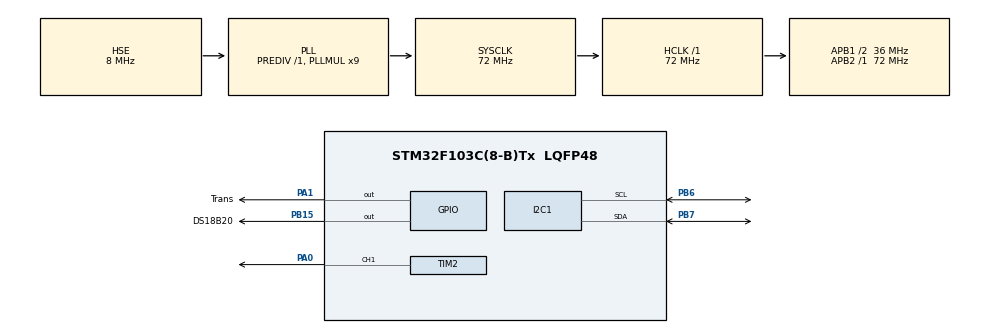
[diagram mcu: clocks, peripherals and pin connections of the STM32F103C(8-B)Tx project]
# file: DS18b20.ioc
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Mcu.Family=STM32F1
Mcu.Name=STM32F103C(8-B)Tx
Mcu.Package=LQFP48
NVIC.PriorityGroup=NVIC_PRIORITYGROUP_4
PA0-WKUP.Signal=S_TIM2_CH1_ETR
PA1.GPIO_Label=Trans
PA1.PinState=GPIO_PIN_RESET
PA1.Signal=GPIO_Output
PA13.Mode=Serial_Wire
PA13.Signal=SYS_JTMS-SWDIO
PA14.Mode=Serial_Wire
PA14.Signal=SYS_JTCK-SWCLK
PB15.GPIO_Label=DS18B20
PB15.Signal=GPIO_Output
PB6.Mode=I2C
PB6.Signal=I2C1_SCL
PB7.Mode=I2C
PB7.Signal=I2C1_SDA
PD0-OSC_IN.Mode=HSE-External-Oscillator
PD0-OSC_IN.Signal=RCC_OSC_IN
PD1-OSC_OUT.Mode=HSE-External-Oscillator
PD1-OSC_OUT.Signal=RCC_OSC_OUT
ProjectManager.HeapSize=0x200
ProjectManager.StackSize=0x400
ProjectManager.TargetToolchain=MDK-ARM V5
RCC.AHBFreq_Value=72000000
RCC.APB1CLKDivider=RCC_HCLK_DIV2
RCC.APB1Freq_Value=36000000
RCC.APB1TimFreq_Value=72000000
RCC.APB2Freq_Value=72000000
RCC.APB2TimFreq_Value=72000000
RCC.HCLKFreq_Value=72000000
RCC.PLLMUL=RCC_PLL_MUL9
RCC.PLLSourceVirtual=RCC_PLLSOURCE_HSE
RCC.SYSCLKFreq_VALUE=72000000
RCC.SYSCLKSource=RCC_SYSCLKSOURCE_PLLCLK
RCC.USBFreq_Value=72000000
SH.S_TIM2_CH1_ETR.0=TIM2_CH1,PWM Generation1 CH1
TIM2.Channel-PWM\ Generation1\ CH1=TIM_CHANNEL_1
TIM2.Period=99
TIM2.Prescaler=8000
TIM2.Pulse-PWM\ Generation1\ CH1=25
TIM4.Prescaler=72-1
VP_TIM2_VS_ClockSourceINT.Mode=Internal
VP_TIM4_VS_ClockSourceINT.Mode=Internal
board=custom

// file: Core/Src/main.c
/* USER CODE BEGIN Header */
/**
  ******************************************************************************
  * @file           : main.c
  * @brief          : Main program body
  ******************************************************************************
  * @attention
  *
  * <h2><center>&copy; Copyright (c) 2023 STMicroelectronics.
  * All rights reserved.</center></h2>
  *
  * This software component is licensed by ST under BSD 3-Clause license,
  * the "License"; You may not use this file except in compliance with the
  * License. You may obtain a copy of the License at:
  *                        opensource.org/licenses/BSD-3-Clause
  *
  ******************************************************************************
  */
/* USER CODE END Header */
#include "main.h"
#include "i2c-lcd.h"
#include "DS18B20.h"
#include "delay_timer.h"
#include "stdio.h"

I2C_HandleTypeDef hi2c1;
TIM_HandleTypeDef htim2;
TIM_HandleTypeDef htim4;

/* USER CODE BEGIN PV */
DS18B20_Name DS1;
float Temp;
float setpoint_temperature = 25;  // Giá tr? m?c tiêu nhi?t d?
float Kp = 1.2;                      // H? s? Proportional
float Ki = 0.1;                      // H? s? Integral
float Kd = 25;                     // H? s? Derivative

float prev_error = 0.0;
float integral = 0.0;
/* USER CODE END PV */

void SystemClock_Config(void);
static void MX_GPIO_Init(void);
static void MX_TIM4_Init(void);
static void MX_I2C1_Init(void);
static void MX_TIM2_Init(void);
void PID_Control(float current_temperature) {
    float error = - setpoint_temperature + current_temperature;
    float pid_output = Kp * error + Ki * integral + Kd * (error - prev_error);

    // Gi? l?i giá tr? PID trong m?c cho phép
    if (pid_output > 100.0) {
        pid_output = 100.0;
    } else if (pid_output < 0.0) {
        pid_output = 0.0;
    }

    // C?p nh?t giá tr? integral và l?i tru?c dó
    integral += error;
    prev_error = error;

    // Áp d?ng giá tr? PID d? di?u khi?n xung PWM
    __HAL_TIM_SET_COMPARE(&htim2, TIM_CHANNEL_1, (uint32_t)(pid_output * htim2.Init.Period / 100.0));
}

int main(void)
{

  /* MCU Configuration--------------------------------------------------------*/

  /* Reset of all peripherals, Initializes the Flash interface and the Systick. */
  HAL_Init();

  /* Configure the system clock */
  SystemClock_Config();

  /* Initialize all configured peripherals */
  MX_GPIO_Init();
  MX_TIM4_Init();
  MX_I2C1_Init();
  MX_TIM2_Init();
	lcd_init();
	HAL_TIM_PWM_Start(&htim2, TIM_CHANNEL_1);
  /* USER CODE BEGIN 2 */
DS18B20_Init(&DS1, &htim4, DS18B20_GPIO_Port, DS18B20_Pin);
char dulieu[20];
  /* USER CODE END 2 */

  /* Infinite loop */
  while (1)
  {
				Temp = DS18B20_ReadTemp(&DS1);
				lcd_clear();
			  lcd_put_cur(0,4);
		    lcd_send_string("DS18B21");
		    lcd_put_cur(1,2);
        lcd_send_string("T = ");
        lcd_put_cur(1,11);
        lcd_send_data(223);
        lcd_put_cur(1,12);
        lcd_send_string("C");
				PID_Control(Temp);
				sprintf(dulieu,"%2.2f",Temp);
		    lcd_send_cmd(0x80|0x46);
		    lcd_send_string(dulieu);
				if (Temp <=30 ) HAL_GPIO_WritePin(Trans_GPIO_Port,Trans_Pin,1);
				else if (Temp >=35 ) HAL_GPIO_WritePin(Trans_GPIO_Port,Trans_Pin,0);
				HAL_Delay(1000);
    /* USER CODE BEGIN 3 */
    /* USER CODE BEGIN 3 */
  }
  /* USER CODE END 3 */
}

void SystemClock_Config(void)
{
  RCC_OscInitTypeDef RCC_OscInitStruct = {0};
  RCC_ClkInitTypeDef RCC_ClkInitStruct = {0};

  /** Initializes the RCC Oscillators according to the specified parameters
  * in the RCC_OscInitTypeDef structure.
  */
  RCC_OscInitStruct.OscillatorType = RCC_OSCILLATORTYPE_HSE;
  RCC_OscInitStruct.HSEState = RCC_HSE_ON;
  RCC_OscInitStruct.HSEPredivValue = RCC_HSE_PREDIV_DIV1;
  RCC_OscInitStruct.HSIState = RCC_HSI_ON;
  RCC_OscInitStruct.PLL.PLLState = RCC_PLL_ON;
  RCC_OscInitStruct.PLL.PLLSource = RCC_PLLSOURCE_HSE;
  RCC_OscInitStruct.PLL.PLLMUL = RCC_PLL_MUL9;
  if (HAL_RCC_OscConfig(&RCC_OscInitStruct) != HAL_OK)
  {
    Error_Handler();
  }
  /** Initializes the CPU, AHB and APB buses clocks
  */
  RCC_ClkInitStruct.ClockType = RCC_CLOCKTYPE_HCLK|RCC_CLOCKTYPE_SYSCLK
                              |RCC_CLOCKTYPE_PCLK1|RCC_CLOCKTYPE_PCLK2;
  RCC_ClkInitStruct.SYSCLKSource = RCC_SYSCLKSOURCE_PLLCLK;
  RCC_ClkInitStruct.AHBCLKDivider = RCC_SYSCLK_DIV1;
  RCC_ClkInitStruct.APB1CLKDivider = RCC_HCLK_DIV2;
  RCC_ClkInitStruct.APB2CLKDivider = RCC_HCLK_DIV1;

  if (HAL_RCC_ClockConfig(&RCC_ClkInitStruct, FLASH_LATENCY_2) != HAL_OK)
  {
    Error_Handler();
  }
}

static void MX_I2C1_Init(void)
{

  hi2c1.Instance = I2C1;
  hi2c1.Init.ClockSpeed = 100000;
  hi2c1.Init.DutyCycle = I2C_DUTYCYCLE_2;
  hi2c1.Init.OwnAddress1 = 0;
  hi2c1.Init.AddressingMode = I2C_ADDRESSINGMODE_7BIT;
  hi2c1.Init.DualAddressMode = I2C_DUALADDRESS_DISABLE;
  hi2c1.Init.OwnAddress2 = 0;
  hi2c1.Init.GeneralCallMode = I2C_GENERALCALL_DISABLE;
  hi2c1.Init.NoStretchMode = I2C_NOSTRETCH_DISABLE;
  if (HAL_I2C_Init(&hi2c1) != HAL_OK)
  {
    Error_Handler();
  }

}

static void MX_TIM2_Init(void)
{

  TIM_ClockConfigTypeDef sClockSourceConfig = {0};
  TIM_MasterConfigTypeDef sMasterConfig = {0};
  TIM_OC_InitTypeDef sConfigOC = {0};

  htim2.Instance = TIM2;
  htim2.Init.Prescaler = 8000;
  htim2.Init.CounterMode = TIM_COUNTERMODE_UP;
  htim2.Init.Period = 99;
  htim2.Init.ClockDivision = TIM_CLOCKDIVISION_DIV1;
  htim2.Init.AutoReloadPreload = TIM_AUTORELOAD_PRELOAD_DISABLE;
  if (HAL_TIM_Base_Init(&htim2) != HAL_OK)
  {
    Error_Handler();
  }
  sClockSourceConfig.ClockSource = TIM_CLOCKSOURCE_INTERNAL;
  if (HAL_TIM_ConfigClockSource(&htim2, &sClockSourceConfig) != HAL_OK)
  {
    Error_Handler();
  }
  if (HAL_TIM_PWM_Init(&htim2) != HAL_OK)
  {
    Error_Handler();
  }
  sMasterConfig.MasterOutputTrigger = TIM_TRGO_RESET;
  sMasterConfig.MasterSlaveMode = TIM_MASTERSLAVEMODE_DISABLE;
  if (HAL_TIMEx_MasterConfigSynchronization(&htim2, &sMasterConfig) != HAL_OK)
  {
    Error_Handler();
  }
  sConfigOC.OCMode = TIM_OCMODE_PWM1;
  sConfigOC.Pulse = 25;
  sConfigOC.OCPolarity = TIM_OCPOLARITY_HIGH;
  sConfigOC.OCFastMode = TIM_OCFAST_DISABLE;
  if (HAL_TIM_PWM_ConfigChannel(&htim2, &sConfigOC, TIM_CHANNEL_1) != HAL_OK)
  {
    Error_Handler();
  }
  HAL_TIM_MspPostInit(&htim2);

}

static void MX_TIM4_Init(void)
{

  TIM_ClockConfigTypeDef sClockSourceConfig = {0};
  TIM_MasterConfigTypeDef sMasterConfig = {0};

  htim4.Instance = TIM4;
  htim4.Init.Prescaler = 72-1;
  htim4.Init.CounterMode = TIM_COUNTERMODE_UP;
  htim4.Init.Period = 65535;
  htim4.Init.ClockDivision = TIM_CLOCKDIVISION_DIV1;
  htim4.Init.AutoReloadPreload = TIM_AUTORELOAD_PRELOAD_DISABLE;
  if (HAL_TIM_Base_Init(&htim4) != HAL_OK)
  {
    Error_Handler();
  }
  sClockSourceConfig.ClockSource = TIM_CLOCKSOURCE_INTERNAL;
  if (HAL_TIM_ConfigClockSource(&htim4, &sClockSourceConfig) != HAL_OK)
  {
    Error_Handler();
  }
  sMasterConfig.MasterOutputTrigger = TIM_TRGO_RESET;
  sMasterConfig.MasterSlaveMode = TIM_MASTERSLAVEMODE_DISABLE;
  if (HAL_TIMEx_MasterConfigSynchronization(&htim4, &sMasterConfig) != HAL_OK)
  {
    Error_Handler();
  }

}

static void MX_GPIO_Init(void)
{
  GPIO_InitTypeDef GPIO_InitStruct = {0};

  /* GPIO Ports Clock Enable */
  __HAL_RCC_GPIOD_CLK_ENABLE();
  __HAL_RCC_GPIOA_CLK_ENABLE();
  __HAL_RCC_GPIOB_CLK_ENABLE();

  /*Configure GPIO pin Output Level */
  HAL_GPIO_WritePin(Trans_GPIO_Port, Trans_Pin, GPIO_PIN_RESET);

  /*Configure GPIO pin Output Level */
  HAL_GPIO_WritePin(DS18B20_GPIO_Port, DS18B20_Pin, GPIO_PIN_RESET);

  /*Configure GPIO pin : Trans_Pin */
  GPIO_InitStruct.Pin = Trans_Pin;
  GPIO_InitStruct.Mode = GPIO_MODE_OUTPUT_PP;
  GPIO_InitStruct.Pull = GPIO_NOPULL;
  GPIO_InitStruct.Speed = GPIO_SPEED_FREQ_LOW;
  HAL_GPIO_Init(Trans_GPIO_Port, &GPIO_InitStruct);

  /*Configure GPIO pin : DS18B20_Pin */
  GPIO_InitStruct.Pin = DS18B20_Pin;
  GPIO_InitStruct.Mode = GPIO_MODE_OUTPUT_PP;
  GPIO_InitStruct.Pull = GPIO_NOPULL;
  GPIO_InitStruct.Speed = GPIO_SPEED_FREQ_LOW;
  HAL_GPIO_Init(DS18B20_GPIO_Port, &GPIO_InitStruct);

}

void Error_Handler(void)
{
}

/************************ (C) COPYRIGHT STMicroelectronics *****END OF FILE****/
